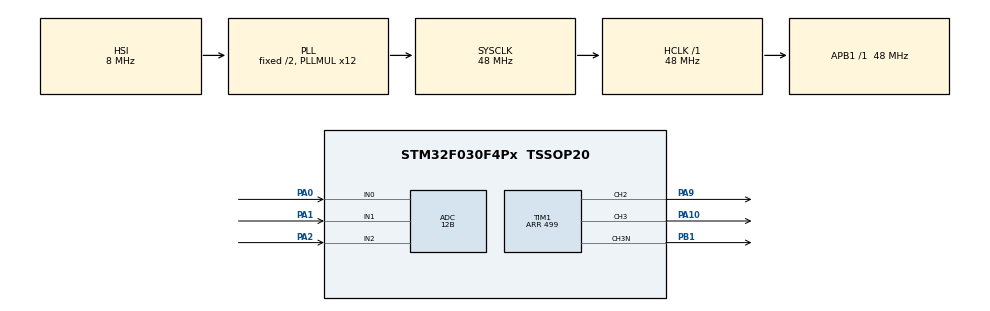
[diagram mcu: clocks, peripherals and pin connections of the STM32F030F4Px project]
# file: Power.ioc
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ADC.ClockPrescaler=ADC_CLOCK_SYNC_PCLK_DIV4
ADC.EOCSelection=ADC_EOC_SEQ_CONV
ADC.Resolution=ADC_RESOLUTION_12B
Mcu.Family=STM32F0
Mcu.Name=STM32F030F4Px
Mcu.Package=TSSOP20
NVIC.ADC1_IRQn=true\:0\:0\:false\:false\:true\:true\:true
NVIC.TIM14_IRQn=true\:0\:0\:false\:false\:true\:true\:true
PA0.Mode=IN0
PA0.Signal=ADC_IN0
PA1.Mode=IN1
PA1.Signal=ADC_IN1
PA10.Signal=S_TIM1_CH3
PA13.Mode=Serial_Wire
PA13.Signal=SYS_SWDIO
PA14.Mode=Serial_Wire
PA14.Signal=SYS_SWCLK
PA2.Mode=IN2
PA2.Signal=ADC_IN2
PA9.Signal=S_TIM1_CH2
PB1.Mode=PWM Generation3 CH3 CH3N
PB1.Signal=TIM1_CH3N
ProjectManager.HeapSize=0x200
ProjectManager.StackSize=0x400
ProjectManager.TargetToolchain=STM32CubeIDE
RCC.AHBFreq_Value=48000000
RCC.APB1Freq_Value=48000000
RCC.APB1TimFreq_Value=48000000
RCC.HCLKFreq_Value=48000000
RCC.PLLMUL=RCC_PLL_MUL12
RCC.SYSCLKFreq_VALUE=48000000
RCC.SYSCLKSource=RCC_SYSCLKSOURCE_PLLCLK
SH.S_TIM1_CH2.0=TIM1_CH2,PWM Generation2 CH2
SH.S_TIM1_CH3.0=TIM1_CH3,PWM Generation3 CH3 CH3N
TIM1.AutoReloadPreload=TIM_AUTORELOAD_PRELOAD_ENABLE
TIM1.Channel-PWM\ Generation2\ CH2=TIM_CHANNEL_2
TIM1.Channel-PWM\ Generation3\ CH3\ CH3N=TIM_CHANNEL_3
TIM1.CounterMode=TIM_COUNTERMODE_CENTERALIGNED1
TIM1.DeadTime=0
TIM1.OCMode_PWM-PWM\ Generation2\ CH2=TIM_OCMODE_PWM1
TIM1.OCNPolarity_3=TIM_OCNPOLARITY_HIGH
TIM1.OCPolarity_2=TIM_OCPOLARITY_LOW
TIM1.Period=499
TIM1.Pulse-PWM\ Generation2\ CH2=400
TIM1.Pulse-PWM\ Generation3\ CH3\ CH3N=100
TIM14.Period=999
TIM14.Prescaler=47
VP_ADC_TempSens_Input.Mode=IN-TempSens
VP_TIM14_VS_ClockSourceINT.Mode=Enable_Timer
board=custom

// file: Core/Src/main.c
/* USER CODE BEGIN Header */
/**
  ******************************************************************************
  * @file           : main.c
  * @brief          : Main program body
  ******************************************************************************
  * @attention
  *
  * <h2><center>&copy; Copyright (c) 2021 STMicroelectronics.
  * All rights reserved.</center></h2>
  *
  * This software component is licensed by ST under BSD 3-Clause license,
  * the "License"; You may not use this file except in compliance with the
  * License. You may obtain a copy of the License at:
  *                        opensource.org/licenses/BSD-3-Clause
  *
  ******************************************************************************
  */
/* USER CODE END Header */
#include "main.h"

ADC_HandleTypeDef hadc;

TIM_HandleTypeDef htim1;
TIM_HandleTypeDef htim14;

void SystemClock_Config(void);
static void MX_GPIO_Init(void);
static void MX_ADC_Init(void);
static void MX_TIM1_Init(void);
static void MX_TIM14_Init(void);

int main(void)
{

  /* MCU Configuration--------------------------------------------------------*/

  /* Reset of all peripherals, Initializes the Flash interface and the Systick. */
  HAL_Init();

  /* Configure the system clock */
  SystemClock_Config();

  /* Initialize all configured peripherals */
  MX_GPIO_Init();
  MX_ADC_Init();
  MX_TIM1_Init();
  MX_TIM14_Init();
  /* USER CODE BEGIN 2 */
  HAL_ADCEx_Calibration_Start(&hadc);
  HAL_TIM_PWM_Start(&htim1, TIM_CHANNEL_3);
  HAL_TIMEx_PWMN_Start(&htim1, TIM_CHANNEL_3);
  HAL_TIM_PWM_Start(&htim1, TIM_CHANNEL_2);
  HAL_TIM_Base_Start_IT(&htim14);
  HAL_ADC_Start_IT(&hadc);
  /* USER CODE END 2 */

  /* Infinite loop */
  while (1)
  {

  }
}

void SystemClock_Config(void)
{
  RCC_OscInitTypeDef RCC_OscInitStruct = {0};
  RCC_ClkInitTypeDef RCC_ClkInitStruct = {0};

  /** Initializes the RCC Oscillators according to the specified parameters
  * in the RCC_OscInitTypeDef structure.
  */
  RCC_OscInitStruct.OscillatorType = RCC_OSCILLATORTYPE_HSI;
  RCC_OscInitStruct.HSIState = RCC_HSI_ON;
  RCC_OscInitStruct.HSICalibrationValue = RCC_HSICALIBRATION_DEFAULT;
  RCC_OscInitStruct.PLL.PLLState = RCC_PLL_ON;
  RCC_OscInitStruct.PLL.PLLSource = RCC_PLLSOURCE_HSI;
  RCC_OscInitStruct.PLL.PLLMUL = RCC_PLL_MUL12;
  RCC_OscInitStruct.PLL.PREDIV = RCC_PREDIV_DIV1;
  if (HAL_RCC_OscConfig(&RCC_OscInitStruct) != HAL_OK)
  {
    Error_Handler();
  }
  /** Initializes the CPU, AHB and APB buses clocks
  */
  RCC_ClkInitStruct.ClockType = RCC_CLOCKTYPE_HCLK|RCC_CLOCKTYPE_SYSCLK
                              |RCC_CLOCKTYPE_PCLK1;
  RCC_ClkInitStruct.SYSCLKSource = RCC_SYSCLKSOURCE_PLLCLK;
  RCC_ClkInitStruct.AHBCLKDivider = RCC_SYSCLK_DIV1;
  RCC_ClkInitStruct.APB1CLKDivider = RCC_HCLK_DIV1;

  if (HAL_RCC_ClockConfig(&RCC_ClkInitStruct, FLASH_LATENCY_1) != HAL_OK)
  {
    Error_Handler();
  }
}

static void MX_ADC_Init(void)
{

  ADC_ChannelConfTypeDef sConfig = {0};

  /** Configure the global features of the ADC (Clock, Resolution, Data Alignment and number of conversion)
  */
  hadc.Instance = ADC1;
  hadc.Init.ClockPrescaler = ADC_CLOCK_SYNC_PCLK_DIV4;
  hadc.Init.Resolution = ADC_RESOLUTION_12B;
  hadc.Init.DataAlign = ADC_DATAALIGN_RIGHT;
  hadc.Init.ScanConvMode = ADC_SCAN_DIRECTION_FORWARD;
  hadc.Init.EOCSelection = ADC_EOC_SEQ_CONV;
  hadc.Init.LowPowerAutoWait = DISABLE;
  hadc.Init.LowPowerAutoPowerOff = DISABLE;
  hadc.Init.ContinuousConvMode = DISABLE;
  hadc.Init.DiscontinuousConvMode = DISABLE;
  hadc.Init.ExternalTrigConv = ADC_SOFTWARE_START;
  hadc.Init.ExternalTrigConvEdge = ADC_EXTERNALTRIGCONVEDGE_NONE;
  hadc.Init.DMAContinuousRequests = DISABLE;
  hadc.Init.Overrun = ADC_OVR_DATA_PRESERVED;
  if (HAL_ADC_Init(&hadc) != HAL_OK)
  {
    Error_Handler();
  }
  /** Configure for the selected ADC regular channel to be converted.
  */
  sConfig.Channel = ADC_CHANNEL_0;
  sConfig.Rank = ADC_RANK_CHANNEL_NUMBER;
  sConfig.SamplingTime = ADC_SAMPLETIME_1CYCLE_5;
  if (HAL_ADC_ConfigChannel(&hadc, &sConfig) != HAL_OK)
  {
    Error_Handler();
  }
  /** Configure for the selected ADC regular channel to be converted.
  */
  sConfig.Channel = ADC_CHANNEL_1;
  if (HAL_ADC_ConfigChannel(&hadc, &sConfig) != HAL_OK)
  {
    Error_Handler();
  }
  /** Configure for the selected ADC regular channel to be converted.
  */
  sConfig.Channel = ADC_CHANNEL_2;
  if (HAL_ADC_ConfigChannel(&hadc, &sConfig) != HAL_OK)
  {
    Error_Handler();
  }
  /** Configure for the selected ADC regular channel to be converted.
  */
  sConfig.Channel = ADC_CHANNEL_TEMPSENSOR;
  if (HAL_ADC_ConfigChannel(&hadc, &sConfig) != HAL_OK)
  {
    Error_Handler();
  }

}

static void MX_TIM1_Init(void)
{

  TIM_MasterConfigTypeDef sMasterConfig = {0};
  TIM_OC_InitTypeDef sConfigOC = {0};
  TIM_BreakDeadTimeConfigTypeDef sBreakDeadTimeConfig = {0};

  htim1.Instance = TIM1;
  htim1.Init.Prescaler = 0;
  htim1.Init.CounterMode = TIM_COUNTERMODE_CENTERALIGNED1;
  htim1.Init.Period = 499;
  htim1.Init.ClockDivision = TIM_CLOCKDIVISION_DIV1;
  htim1.Init.RepetitionCounter = 0;
  htim1.Init.AutoReloadPreload = TIM_AUTORELOAD_PRELOAD_ENABLE;
  if (HAL_TIM_PWM_Init(&htim1) != HAL_OK)
  {
    Error_Handler();
  }
  sMasterConfig.MasterOutputTrigger = TIM_TRGO_RESET;
  sMasterConfig.MasterSlaveMode = TIM_MASTERSLAVEMODE_DISABLE;
  if (HAL_TIMEx_MasterConfigSynchronization(&htim1, &sMasterConfig) != HAL_OK)
  {
    Error_Handler();
  }
  sConfigOC.OCMode = TIM_OCMODE_PWM1;
  sConfigOC.Pulse = 400;
  sConfigOC.OCPolarity = TIM_OCPOLARITY_LOW;
  sConfigOC.OCNPolarity = TIM_OCNPOLARITY_HIGH;
  sConfigOC.OCFastMode = TIM_OCFAST_DISABLE;
  sConfigOC.OCIdleState = TIM_OCIDLESTATE_RESET;
  sConfigOC.OCNIdleState = TIM_OCNIDLESTATE_RESET;
  if (HAL_TIM_PWM_ConfigChannel(&htim1, &sConfigOC, TIM_CHANNEL_2) != HAL_OK)
  {
    Error_Handler();
  }
  sConfigOC.Pulse = 100;
  sConfigOC.OCPolarity = TIM_OCPOLARITY_HIGH;
  if (HAL_TIM_PWM_ConfigChannel(&htim1, &sConfigOC, TIM_CHANNEL_3) != HAL_OK)
  {
    Error_Handler();
  }
  sBreakDeadTimeConfig.OffStateRunMode = TIM_OSSR_DISABLE;
  sBreakDeadTimeConfig.OffStateIDLEMode = TIM_OSSI_DISABLE;
  sBreakDeadTimeConfig.LockLevel = TIM_LOCKLEVEL_OFF;
  sBreakDeadTimeConfig.DeadTime = 0;
  sBreakDeadTimeConfig.BreakState = TIM_BREAK_DISABLE;
  sBreakDeadTimeConfig.BreakPolarity = TIM_BREAKPOLARITY_HIGH;
  sBreakDeadTimeConfig.AutomaticOutput = TIM_AUTOMATICOUTPUT_DISABLE;
  if (HAL_TIMEx_ConfigBreakDeadTime(&htim1, &sBreakDeadTimeConfig) != HAL_OK)
  {
    Error_Handler();
  }
  HAL_TIM_MspPostInit(&htim1);

}

static void MX_TIM14_Init(void)
{

  htim14.Instance = TIM14;
  htim14.Init.Prescaler = 47;
  htim14.Init.CounterMode = TIM_COUNTERMODE_UP;
  htim14.Init.Period = 999;
  htim14.Init.ClockDivision = TIM_CLOCKDIVISION_DIV1;
  htim14.Init.AutoReloadPreload = TIM_AUTORELOAD_PRELOAD_DISABLE;
  if (HAL_TIM_Base_Init(&htim14) != HAL_OK)
  {
    Error_Handler();
  }

}

static void MX_GPIO_Init(void)
{

  /* GPIO Ports Clock Enable */
  __HAL_RCC_GPIOA_CLK_ENABLE();
  __HAL_RCC_GPIOB_CLK_ENABLE();

}

/* USER CODE BEGIN 4 */
void HAL_ADC_ConvCpltCallback(ADC_HandleTypeDef* hadc)
{
	uint32_t data = HAL_ADC_GetValue(hadc);
}

/* USER CODE END 4 */

void Error_Handler(void)
{
}

/************************ (C) COPYRIGHT STMicroelectronics *****END OF FILE****/
